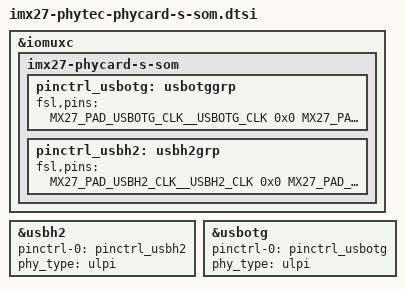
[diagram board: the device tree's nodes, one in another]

&iomuxc {
	imx27-phycard-s-som {
		pinctrl_usbotg: usbotggrp {
			fsl,pins = <
				MX27_PAD_USBOTG_CLK__USBOTG_CLK 0x0
				MX27_PAD_USBOTG_DIR__USBOTG_DIR 0x0
				MX27_PAD_USBOTG_NXT__USBOTG_NXT 0x0
				MX27_PAD_USBOTG_STP__USBOTG_STP 0x0
				MX27_PAD_USBOTG_DATA0__USBOTG_DATA0 0x0
				MX27_PAD_USBOTG_DATA1__USBOTG_DATA1 0x0
				MX27_PAD_USBOTG_DATA2__USBOTG_DATA2 0x0
				MX27_PAD_USBOTG_DATA3__USBOTG_DATA3 0x0
				MX27_PAD_USBOTG_DATA4__USBOTG_DATA4 0x0
				MX27_PAD_USBOTG_DATA5__USBOTG_DATA5 0x0
				MX27_PAD_USBOTG_DATA6__USBOTG_DATA6 0x0
				MX27_PAD_USBOTG_DATA7__USBOTG_DATA7 0x0
			>;
		};

		pinctrl_usbh2: usbh2grp {
			fsl,pins = <
				MX27_PAD_USBH2_CLK__USBH2_CLK 0x0
				MX27_PAD_USBH2_DIR__USBH2_DIR 0x0
				MX27_PAD_USBH2_NXT__USBH2_NXT 0x0
				MX27_PAD_USBH2_STP__USBH2_STP 0x0
				MX27_PAD_CSPI2_SCLK__USBH2_DATA0 0x0
				MX27_PAD_CSPI2_MOSI__USBH2_DATA1 0x0
				MX27_PAD_CSPI2_MISO__USBH2_DATA2 0x0
				MX27_PAD_CSPI2_SS1__USBH2_DATA3 0x0
				MX27_PAD_CSPI2_SS2__USBH2_DATA4 0x0
				MX27_PAD_CSPI1_SS2__USBH2_DATA5 0x0
				MX27_PAD_CSPI2_SS0__USBH2_DATA6 0x0
				MX27_PAD_USBH2_DATA7__USBH2_DATA7 0x0
			>;
		};
	};
};

&usbh2 {
	pinctrl-names = "default";
	pinctrl-0 = <&pinctrl_usbh2>;
	phy_type = "ulpi";
};

&usbotg {
	pinctrl-names = "default";
	pinctrl-0 = <&pinctrl_usbotg>;
	phy_type = "ulpi";
};
